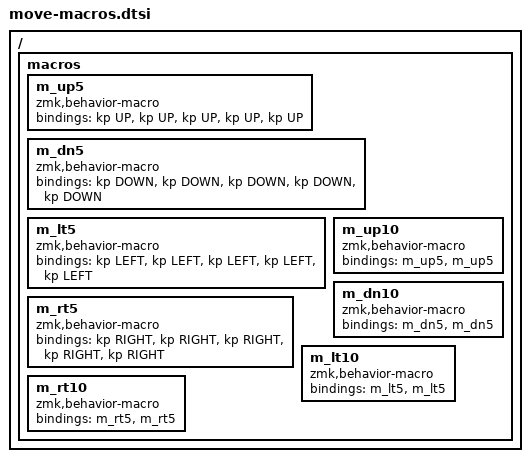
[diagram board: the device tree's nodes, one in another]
/ {
    macros {
        m_up5: m_up5 {
            compatible = "zmk,behavior-macro";
            #binding-cells = <0>;
            bindings = <&kp UP &kp UP &kp UP &kp UP &kp UP>;
        };

        m_dn5: m_dn5 {
            compatible = "zmk,behavior-macro";
            #binding-cells = <0>;
            bindings = <&kp DOWN &kp DOWN &kp DOWN &kp DOWN &kp DOWN>;
        };

        m_lt5: m_lt5 {
            compatible = "zmk,behavior-macro";
            #binding-cells = <0>;
            bindings = <&kp LEFT &kp LEFT &kp LEFT &kp LEFT &kp LEFT>;
        };

        m_rt5: m_rt5 {
            compatible = "zmk,behavior-macro";
            #binding-cells = <0>;
            bindings = <&kp RIGHT &kp RIGHT &kp RIGHT &kp RIGHT &kp RIGHT>;
        };

        m_up10: m_up10 {
            compatible = "zmk,behavior-macro";
            #binding-cells = <0>;
            bindings = <&m_up5 &m_up5>;
        };

        m_dn10: m_dn10 {
            compatible = "zmk,behavior-macro";
            #binding-cells = <0>;
            bindings = <&m_dn5 &m_dn5>;
        };

        m_lt10: m_lt10 {
            compatible = "zmk,behavior-macro";
            #binding-cells = <0>;
            bindings = <&m_lt5 &m_lt5>;
        };

        m_rt10: m_rt10 {
            compatible = "zmk,behavior-macro";
            #binding-cells = <0>;
            bindings = <&m_rt5 &m_rt5>;
        };
    };
};
